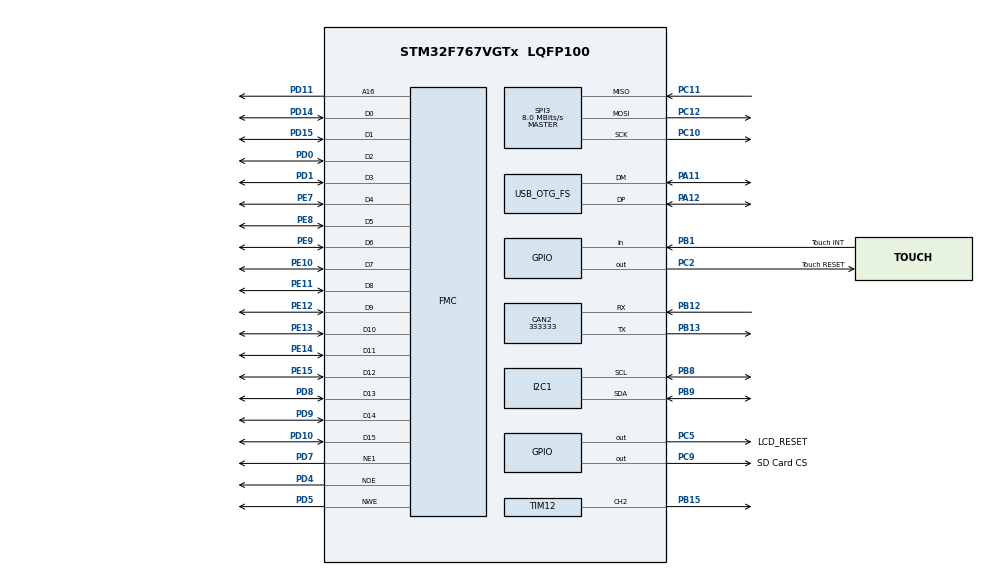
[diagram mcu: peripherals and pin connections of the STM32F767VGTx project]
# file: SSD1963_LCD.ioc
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CAN2.CalculateBaudRate=333333
CAN2.CalculateTimeBit=3000
CAN2.CalculateTimeQuantum=1000.0
CORTEX_M7.AccessPermission_S-Cortex_Memory_Protection_Unit_Region1_Settings_S=MPU_REGION_FULL_ACCESS
CORTEX_M7.AccessPermission_Spec=MPU_REGION_PRIV_RW
CORTEX_M7.BaseAddress_S-Cortex_Memory_Protection_Unit_Region1_Settings_S=0x60000000
CORTEX_M7.DisableExec_S-Cortex_Memory_Protection_Unit_Region1_Settings_S=MPU_INSTRUCTION_ACCESS_DISABLE
CORTEX_M7.DisableExec_Spec=MPU_INSTRUCTION_ACCESS_ENABLE
CORTEX_M7.Enable_S-Cortex_Memory_Protection_Unit_Region1_Settings_S=MPU_REGION_ENABLE
CORTEX_M7.IsShareable_S-Cortex_Memory_Protection_Unit_Region1_Settings_S=MPU_ACCESS_SHAREABLE
CORTEX_M7.Size_S-Cortex_Memory_Protection_Unit_Region1_Settings_S=MPU_REGION_SIZE_8MB
CORTEX_M7.default_mode_Activation=1
FMC.AddressSetupTime1=2
FMC.DataSetupTime1=10
FMC.ExtendedMode1=FMC_EXTENDED_MODE_DISABLE
Mcu.Family=STM32F7
Mcu.Name=STM32F767VGTx
Mcu.Package=LQFP100
NVIC.CAN2_RX0_IRQn=true\:0\:0\:false\:false\:true\:true\:true\:true
NVIC.CAN2_RX1_IRQn=true\:0\:0\:false\:false\:true\:true\:true\:true
NVIC.CAN2_TX_IRQn=true\:0\:0\:false\:false\:true\:true\:true\:true
NVIC.PriorityGroup=NVIC_PRIORITYGROUP_4
PA11.Mode=Device_Only
PA11.Signal=USB_OTG_FS_DM
PA12.Mode=Device_Only
PA12.Signal=USB_OTG_FS_DP
PA13.Signal=SYS_JTMS-SWDIO
PA14.Signal=SYS_JTCK-SWCLK
PB1.GPIO_Label=Touch INT
PB1.Signal=GPIO_Input
PB12.Mode=CAN_Activate
PB12.Signal=CAN2_RX
PB13.Mode=CAN_Activate
PB13.Signal=CAN2_TX
PB15.Signal=S_TIM12_CH2
PB8.Mode=I2C
PB8.Signal=I2C1_SCL
PB9.Mode=I2C
PB9.Signal=I2C1_SDA
PC10.Mode=Full_Duplex_Master
PC10.Signal=SPI3_SCK
PC11.Mode=Full_Duplex_Master
PC11.Signal=SPI3_MISO
PC12.Mode=Full_Duplex_Master
PC12.Signal=SPI3_MOSI
PC2.GPIO_Label=Touch RESET
PC2.PinState=GPIO_PIN_SET
PC2.Signal=GPIO_Output
PC5.GPIO_Label=LCD_RESET
PC5.PinState=GPIO_PIN_SET
PC5.Signal=GPIO_Output
PC9.GPIO_Label=SD Card CS
PC9.PinState=GPIO_PIN_SET
PC9.Signal=GPIO_Output
PD0.Signal=FMC_D2_DA2
PD1.Signal=FMC_D3_DA3
PD10.Signal=FMC_D15_DA15
PD11.Signal=FMC_A16_CLE
PD14.Signal=FMC_D0_DA0
PD15.Signal=FMC_D1_DA1
PD4.Signal=FMC_NOE
PD5.Signal=FMC_NWE
PD7.Mode=NorPsramChipSelect1_1
PD7.Signal=FMC_NE1
PD8.Signal=FMC_D13_DA13
PD9.Signal=FMC_D14_DA14
PE10.Signal=FMC_D7_DA7
PE11.Signal=FMC_D8_DA8
PE12.Signal=FMC_D9_DA9
PE13.Signal=FMC_D10_DA10
PE14.Signal=FMC_D11_DA11
PE15.Signal=FMC_D12_DA12
PE7.Signal=FMC_D4_DA4
PE8.Signal=FMC_D5_DA5
PE9.Signal=FMC_D6_DA6
PH0/OSC_IN.Mode=HSE-External-Oscillator
PH0/OSC_IN.Signal=RCC_OSC_IN
PH1/OSC_OUT.Mode=HSE-External-Oscillator
PH1/OSC_OUT.Signal=RCC_OSC_OUT
ProjectManager.HeapSize=0x2000
ProjectManager.StackSize=0x2000
ProjectManager.TargetToolchain=CMake
RCC.HSE_VALUE=8000000
RCC.HSI_VALUE=16000000
RCC.PLLM=4
RCC.PLLN=96
RCC.PLLQ=4
RCC.USBFreq_Value=48000000
RCC.VCOOutputFreq_Value=192000000
SH.FMC_A16_CLE.0=FMC_A16,A16_1
SH.FMC_D0_DA0.0=FMC_D0,16b-d1
SH.FMC_D10_DA10.0=FMC_D10,16b-d1
SH.FMC_D11_DA11.0=FMC_D11,16b-d1
SH.FMC_D12_DA12.0=FMC_D12,16b-d1
SH.FMC_D13_DA13.0=FMC_D13,16b-d1
SH.FMC_D14_DA14.0=FMC_D14,16b-d1
SH.FMC_D15_DA15.0=FMC_D15,16b-d1
SH.FMC_D1_DA1.0=FMC_D1,16b-d1
SH.FMC_D2_DA2.0=FMC_D2,16b-d1
SH.FMC_D3_DA3.0=FMC_D3,16b-d1
SH.FMC_D4_DA4.0=FMC_D4,16b-d1
SH.FMC_D5_DA5.0=FMC_D5,16b-d1
SH.FMC_D6_DA6.0=FMC_D6,16b-d1
SH.FMC_D7_DA7.0=FMC_D7,16b-d1
SH.FMC_D8_DA8.0=FMC_D8,16b-d1
SH.FMC_D9_DA9.0=FMC_D9,16b-d1
SH.FMC_NOE.0=FMC_NOE,Lcd1
SH.FMC_NWE.0=FMC_NWE,Lcd1
SH.S_TIM12_CH2.0=TIM12_CH2,PWM Generation2 CH2
SPI3.CalculateBaudRate=8.0 MBits/s
SPI3.Direction=SPI_DIRECTION_2LINES
SPI3.Mode=SPI_MODE_MASTER
SPI3.VirtualType=VM_MASTER
TIM12.Channel-PWM\ Generation2\ CH2=TIM_CHANNEL_2
USB_OTG_FS.VirtualMode=Device_Only
board=custom

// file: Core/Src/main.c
/* USER CODE BEGIN Header */
/**
  ******************************************************************************
  * @file           : main.c
  * @brief          : Main program body
  ******************************************************************************
  * @attention
  *
  * Copyright (c) 2026 STMicroelectronics.
  * All rights reserved.
  *
  * This software is licensed under terms that can be found in the LICENSE file
  * in the root directory of this software component.
  * If no LICENSE file comes with this software, it is provided AS-IS.
  *
  ******************************************************************************
  */
/* USER CODE END Header */
#include "main.h"
#include "can.h"
#include "i2c.h"
#include "spi.h"
#include "tim.h"
#include "usb_otg.h"
#include "gpio.h"
#include "fmc.h"

#include "ssd1963.h"

void SystemClock_Config(void);
static void MPU_Config(void);

int main(void)
{

  /* MPU Configuration--------------------------------------------------------*/
  MPU_Config();

  /* MCU Configuration--------------------------------------------------------*/

  /* Reset of all peripherals, Initializes the Flash interface and the Systick. */
  HAL_Init();

  /* Configure the system clock */
  SystemClock_Config();

  /* Initialize all configured peripherals */
  MX_GPIO_Init();
  MX_FMC_Init();
  MX_CAN2_Init();
  MX_I2C1_Init();
  MX_SPI3_Init();
  MX_TIM12_Init();
  MX_USB_OTG_FS_PCD_Init();
  /* USER CODE BEGIN 2 */
  // Start backlight PWM (your external brightness control on PB15)
  HAL_TIM_PWM_Start(&htim12, TIM_CHANNEL_2);
  __HAL_TIM_SET_COMPARE(&htim12, TIM_CHANNEL_2, __HAL_TIM_GET_AUTORELOAD(&htim12) / 2); // 50%
  SSD1963_Init();
  /* USER CODE END 2 */

  /* Infinite loop */
  /* USER CODE BEGIN WHILE */
  __enable_irq();
  while (1)
  {
    /* USER CODE END WHILE */
    SSD1963_Fill(RGB565(255, 0, 0));   // solid red
    HAL_Delay(500);
    SSD1963_Fill(RGB565(0, 255, 0));   // solid green
    HAL_Delay(500);
    SSD1963_Fill(RGB565(0, 0, 255));   // solid blue
    HAL_Delay(500);
    SSD1963_Fill(RGB565(255, 255, 255)); // white
    HAL_Delay(500);
  }
}

void SystemClock_Config(void)
{
  RCC_OscInitTypeDef RCC_OscInitStruct = {0};
  RCC_ClkInitTypeDef RCC_ClkInitStruct = {0};

  /** Configure the main internal regulator output voltage
  */
  __HAL_RCC_PWR_CLK_ENABLE();
  __HAL_PWR_VOLTAGESCALING_CONFIG(PWR_REGULATOR_VOLTAGE_SCALE3);

  /** Initializes the RCC Oscillators according to the specified parameters
  * in the RCC_OscInitTypeDef structure.
  */
  RCC_OscInitStruct.OscillatorType = RCC_OSCILLATORTYPE_HSI|RCC_OSCILLATORTYPE_HSE;
  RCC_OscInitStruct.HSEState = RCC_HSE_ON;
  RCC_OscInitStruct.HSIState = RCC_HSI_ON;
  RCC_OscInitStruct.HSICalibrationValue = RCC_HSICALIBRATION_DEFAULT;
  RCC_OscInitStruct.PLL.PLLState = RCC_PLL_ON;
  RCC_OscInitStruct.PLL.PLLSource = RCC_PLLSOURCE_HSE;
  RCC_OscInitStruct.PLL.PLLM = 4;
  RCC_OscInitStruct.PLL.PLLN = 96;
  RCC_OscInitStruct.PLL.PLLP = RCC_PLLP_DIV2;
  RCC_OscInitStruct.PLL.PLLQ = 4;
  RCC_OscInitStruct.PLL.PLLR = 2;
  if (HAL_RCC_OscConfig(&RCC_OscInitStruct) != HAL_OK)
  {
    Error_Handler();
  }

  /** Initializes the CPU, AHB and APB buses clocks
  */
  RCC_ClkInitStruct.ClockType = RCC_CLOCKTYPE_HCLK|RCC_CLOCKTYPE_SYSCLK
                              |RCC_CLOCKTYPE_PCLK1|RCC_CLOCKTYPE_PCLK2;
  RCC_ClkInitStruct.SYSCLKSource = RCC_SYSCLKSOURCE_HSI;
  RCC_ClkInitStruct.AHBCLKDivider = RCC_SYSCLK_DIV1;
  RCC_ClkInitStruct.APB1CLKDivider = RCC_HCLK_DIV1;
  RCC_ClkInitStruct.APB2CLKDivider = RCC_HCLK_DIV1;

  if (HAL_RCC_ClockConfig(&RCC_ClkInitStruct, FLASH_LATENCY_0) != HAL_OK)
  {
    Error_Handler();
  }
}

 /* MPU Configuration */

void MPU_Config(void)
{
  MPU_Region_InitTypeDef MPU_InitStruct = {0};

  /* Disables the MPU */
  HAL_MPU_Disable();

  /** Initializes and configures the Region and the memory to be protected
  */
  MPU_InitStruct.Enable = MPU_REGION_ENABLE;
  MPU_InitStruct.Number = MPU_REGION_NUMBER0;
  MPU_InitStruct.BaseAddress = 0x0;
  MPU_InitStruct.Size = MPU_REGION_SIZE_4GB;
  MPU_InitStruct.SubRegionDisable = 0x87;
  MPU_InitStruct.TypeExtField = MPU_TEX_LEVEL0;
  MPU_InitStruct.AccessPermission = MPU_REGION_PRIV_RW;
  MPU_InitStruct.DisableExec = MPU_INSTRUCTION_ACCESS_ENABLE;
  MPU_InitStruct.IsShareable = MPU_ACCESS_SHAREABLE;
  MPU_InitStruct.IsCacheable = MPU_ACCESS_NOT_CACHEABLE;
  MPU_InitStruct.IsBufferable = MPU_ACCESS_NOT_BUFFERABLE;

  HAL_MPU_ConfigRegion(&MPU_InitStruct);

  /** Initializes and configures the Region and the memory to be protected
  */
  MPU_InitStruct.Number = MPU_REGION_NUMBER1;
  MPU_InitStruct.BaseAddress = 0x60000000;
  MPU_InitStruct.Size = MPU_REGION_SIZE_8MB;
  MPU_InitStruct.SubRegionDisable = 0x0;
  MPU_InitStruct.AccessPermission = MPU_REGION_FULL_ACCESS;
  MPU_InitStruct.DisableExec = MPU_INSTRUCTION_ACCESS_DISABLE;

  HAL_MPU_ConfigRegion(&MPU_InitStruct);
  /* Enables the MPU */
  HAL_MPU_Enable(MPU_PRIVILEGED_DEFAULT);

}

void Error_Handler(void)
{
  __disable_irq();
  while (1)
  {
  }
}
